# MCU_ARMSS0_DBG_RD0 register map
Vendor: Texas Instruments
Peripheral module from a debugger description file (folder am65x).
Registers are 32-bit, read-write, reset 0x70007000 unless marked. A register's access mark holds for its fields unless they carry their own. Offsets are as the file gives them; lines under a group give offsets from that group; [hi:lo] are bit positions; {n}, {i} and the like mark numbered series; 'fields as' and 'values as' point back to an identical list; <NAME> marks a mode.

## MCU_ARMSS0_DBG_RD0
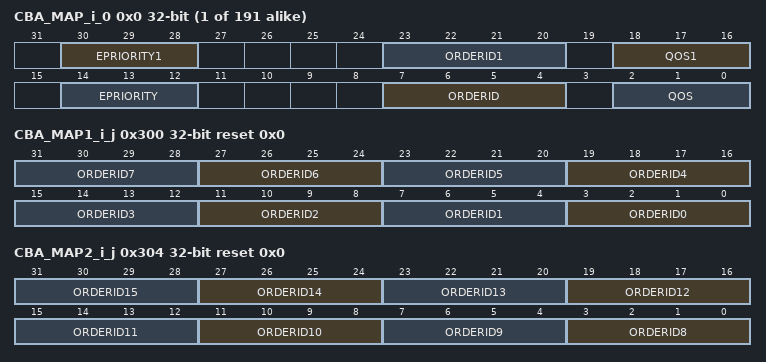
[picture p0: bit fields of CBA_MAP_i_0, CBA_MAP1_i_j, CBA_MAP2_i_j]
{0x0+4i} CBA_MAP_i_{i} (i=0..190) — The Map Register defines the fields for the master per channel. Channel N is calculated as b*2 and N+1 is b*2+1, where: b = 0h to BFh. Offset = 0h + (i * 400h), where: i = 0h to 7h
  [30:28] EPRIORITY1 — epriority signal for channel N+1.
  [23:20] ORDERID1 — Initial order ID value for channel N+1.
  [18:16] QOS1 — qos signal for channel N+1.
  [14:12] EPRIORITY — epriority signal for channel N.
  [7:4] ORDERID — Initial order ID value for channel N.
  [2:0] QOS — qos signal for channel N.
0x300 CBA_MAP1_i_j reset 0x0 — The Group Map Register 1 defines the final order ID for the master group j from input order ID values of 0 to 7. Offset = 300h + (i * 400h) + (j * 8h), where: i = 0h to 7h, j = 0h to 1Fh
  [4n+3:4n] ORDERID{n} (n=0..7) — Final order ID value for initial order ID value of {n}.
0x304 CBA_MAP2_i_j reset 0x0 — The Group Map Register 2 defines the final order ID for the master group j from input order ID values of 8 to 15. Offset = 304h + (i * 400h) + (j * 8h), where: i = 0h to 7h, j = 0h to 1Fh
  [4n-29:4n-32] ORDERID{n} (n=8..15) — Final order ID value for initial order ID value of {n}.
